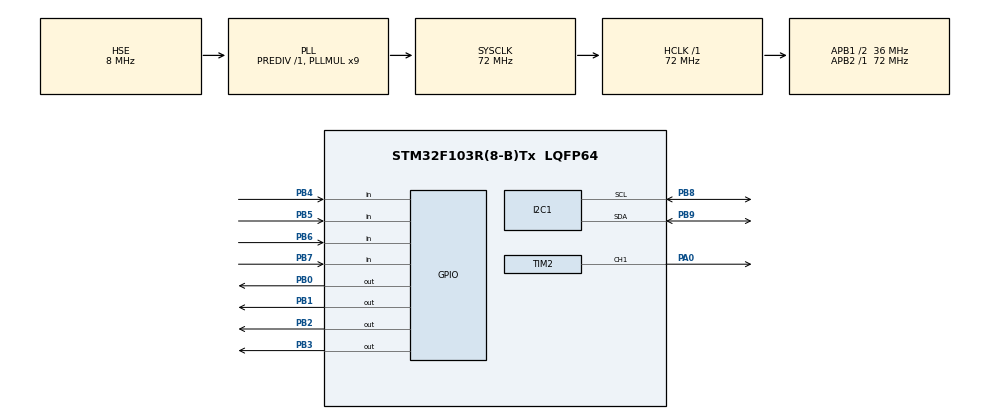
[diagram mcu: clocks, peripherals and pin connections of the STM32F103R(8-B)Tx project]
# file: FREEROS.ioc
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FREERTOS.Mutexes01=angleMutex,Dynamic,NULL,Available
FREERTOS.Tasks01=defaultTask,-2,128,StartDefaultTask,Default,NULL,Dynamic,NULL,NULL;KeypadTask,0,256,StartKeypadTask,Default,NULL,Dynamic,NULL,NULL;ServoTask,1,256,StartServoTask,Default,NULL,Dynamic,NULL,NULL;LCDTask,0,256,StartLCDTask,Default,NULL,Dynamic,NULL,NULL
FREERTOS.configTOTAL_HEAP_SIZE=8192
FREERTOS.configUSE_NEWLIB_REENTRANT=1
Mcu.Family=STM32F1
Mcu.Name=STM32F103R(8-B)Tx
Mcu.Package=LQFP64
NVIC.PriorityGroup=NVIC_PRIORITYGROUP_4
NVIC.TIM1_UP_IRQn=true\:5\:0\:false\:false\:true\:true\:true\:true\:true
NVIC.TIM2_IRQn=true\:5\:0\:false\:false\:true\:true\:true\:true\:true
NVIC.TIM4_IRQn=true\:15\:0\:false\:false\:true\:false\:false\:true\:true
NVIC.TimeBase=TIM4_IRQn
NVIC.TimeBaseIP=TIM4
PA0-WKUP.Signal=S_TIM2_CH1_ETR
PB0.Signal=GPIO_Output
PB1.Signal=GPIO_Output
PB2.Signal=GPIO_Output
PB3.Signal=GPIO_Output
PB4.GPIO_PuPd=GPIO_PULLUP
PB4.Signal=GPIO_Input
PB5.GPIO_PuPd=GPIO_PULLUP
PB5.Signal=GPIO_Input
PB6.GPIO_PuPd=GPIO_PULLUP
PB6.Signal=GPIO_Input
PB7.GPIO_PuPd=GPIO_PULLUP
PB7.Signal=GPIO_Input
PB8.Mode=I2C
PB8.Signal=I2C1_SCL
PB9.Mode=I2C
PB9.Signal=I2C1_SDA
PD0-OSC_IN.Mode=HSE-External-Oscillator
PD0-OSC_IN.Signal=RCC_OSC_IN
PD1-OSC_OUT.Mode=HSE-External-Oscillator
PD1-OSC_OUT.Signal=RCC_OSC_OUT
ProjectManager.HeapSize=0x200
ProjectManager.StackSize=0x400
ProjectManager.TargetToolchain=STM32CubeIDE
RCC.AHBFreq_Value=72000000
RCC.APB1CLKDivider=RCC_HCLK_DIV2
RCC.APB1Freq_Value=36000000
RCC.APB1TimFreq_Value=72000000
RCC.APB2Freq_Value=72000000
RCC.APB2TimFreq_Value=72000000
RCC.HCLKFreq_Value=72000000
RCC.PLLMUL=RCC_PLL_MUL9
RCC.PLLSourceVirtual=RCC_PLLSOURCE_HSE
RCC.SYSCLKFreq_VALUE=72000000
RCC.SYSCLKSource=RCC_SYSCLKSOURCE_PLLCLK
RCC.USBFreq_Value=72000000
SH.S_TIM2_CH1_ETR.0=TIM2_CH1,PWM Generation1 CH1
TIM2.Channel-PWM\ Generation1\ CH1=TIM_CHANNEL_1
TIM2.Period=20 - 1
TIM2.Prescaler=720 - 1
VP_FREERTOS_VS_CMSIS_V1.Mode=CMSIS_V1
VP_SYS_VS_ND.Mode=No_Debug
VP_SYS_VS_tim4.Mode=TIM4
VP_TIM1_VS_ClockSourceINT.Mode=Internal
VP_TIM2_VS_ClockSourceINT.Mode=Internal
board=custom

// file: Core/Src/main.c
/* USER CODE BEGIN Header */
/**
  ******************************************************************************
  * @file           : main.c
  * @brief          : Main program body
  ******************************************************************************
  * @attention
  *
  * Copyright (c) 2026 STMicroelectronics.
  * All rights reserved.
  *
  * This software is licensed under terms that can be found in the LICENSE file
  * in the root directory of this software component.
  * If no LICENSE file comes with this software, it is provided AS-IS.
  *
  ******************************************************************************
  */
/* USER CODE END Header */
#include "main.h"
#include "cmsis_os.h"

/* USER CODE BEGIN Includes */
#include "keypad.h"
#include "lcd_i2c.h"
#include "servo.h"
#include <stdio.h>
#include <string.h>
#include <stdlib.h>
/* USER CODE END Includes */

I2C_HandleTypeDef hi2c1;

TIM_HandleTypeDef htim1;
TIM_HandleTypeDef htim2;

osThreadId defaultTaskHandle;
osThreadId KeypadTaskHandle;
osThreadId ServoTaskHandle;
osThreadId LCDTaskHandle;
osMutexId angleMutexHandle;
/* USER CODE BEGIN PV */
/* Shared variables — all protected by angleMutex */
volatile uint8_t targetAngle = 90;    /* confirmed servo angle (0-180) */
volatile char    inputDisplay[5] = ""; /* digits being typed right now   */
/* USER CODE END PV */

void SystemClock_Config(void);
static void MX_GPIO_Init(void);
static void MX_I2C1_Init(void);
static void MX_TIM1_Init(void);
static void MX_TIM2_Init(void);
void StartDefaultTask(void const * argument);
void StartKeypadTask(void const * argument);
void StartServoTask(void const * argument);
void StartLCDTask(void const * argument);

int main(void)
{

  /* MCU Configuration--------------------------------------------------------*/

  /* Reset of all peripherals, Initializes the Flash interface and the Systick. */
  HAL_Init();

  /* Configure the system clock */
  SystemClock_Config();

  /* Initialize all configured peripherals */
  MX_GPIO_Init();
  MX_I2C1_Init();
  MX_TIM1_Init();
  MX_TIM2_Init();

  /* Create the mutex(es) */
  /* definition and creation of angleMutex */
  osMutexDef(angleMutex);
  angleMutexHandle = osMutexCreate(osMutex(angleMutex));

  /* Create the thread(s) */
  /* definition and creation of defaultTask */
  osThreadDef(defaultTask, StartDefaultTask, osPriorityLow, 0, 128);
  defaultTaskHandle = osThreadCreate(osThread(defaultTask), NULL);

  /* definition and creation of KeypadTask */
  osThreadDef(KeypadTask, StartKeypadTask, osPriorityNormal, 0, 256);
  KeypadTaskHandle = osThreadCreate(osThread(KeypadTask), NULL);

  /* definition and creation of ServoTask */
  osThreadDef(ServoTask, StartServoTask, osPriorityAboveNormal, 0, 256);
  ServoTaskHandle = osThreadCreate(osThread(ServoTask), NULL);

  /* definition and creation of LCDTask */
  osThreadDef(LCDTask, StartLCDTask, osPriorityNormal, 0, 256);
  LCDTaskHandle = osThreadCreate(osThread(LCDTask), NULL);

  /* Start scheduler */
  osKernelStart();

  /* We should never get here as control is now taken by the scheduler */

  /* Infinite loop */
  while (1)
  {

  }
}

void SystemClock_Config(void)
{
  RCC_OscInitTypeDef RCC_OscInitStruct = {0};
  RCC_ClkInitTypeDef RCC_ClkInitStruct = {0};

  /** Initializes the RCC Oscillators according to the specified parameters
  * in the RCC_OscInitTypeDef structure.
  */
  RCC_OscInitStruct.OscillatorType = RCC_OSCILLATORTYPE_HSE;
  RCC_OscInitStruct.HSEState = RCC_HSE_ON;
  RCC_OscInitStruct.HSEPredivValue = RCC_HSE_PREDIV_DIV1;
  RCC_OscInitStruct.HSIState = RCC_HSI_ON;
  RCC_OscInitStruct.PLL.PLLState = RCC_PLL_ON;
  RCC_OscInitStruct.PLL.PLLSource = RCC_PLLSOURCE_HSE;
  RCC_OscInitStruct.PLL.PLLMUL = RCC_PLL_MUL9;
  if (HAL_RCC_OscConfig(&RCC_OscInitStruct) != HAL_OK)
  {
    Error_Handler();
  }

  /** Initializes the CPU, AHB and APB buses clocks
  */
  RCC_ClkInitStruct.ClockType = RCC_CLOCKTYPE_HCLK|RCC_CLOCKTYPE_SYSCLK
                              |RCC_CLOCKTYPE_PCLK1|RCC_CLOCKTYPE_PCLK2;
  RCC_ClkInitStruct.SYSCLKSource = RCC_SYSCLKSOURCE_PLLCLK;
  RCC_ClkInitStruct.AHBCLKDivider = RCC_SYSCLK_DIV1;
  RCC_ClkInitStruct.APB1CLKDivider = RCC_HCLK_DIV2;
  RCC_ClkInitStruct.APB2CLKDivider = RCC_HCLK_DIV1;

  if (HAL_RCC_ClockConfig(&RCC_ClkInitStruct, FLASH_LATENCY_2) != HAL_OK)
  {
    Error_Handler();
  }
}

static void MX_I2C1_Init(void)
{

  hi2c1.Instance = I2C1;
  hi2c1.Init.ClockSpeed = 100000;
  hi2c1.Init.DutyCycle = I2C_DUTYCYCLE_2;
  hi2c1.Init.OwnAddress1 = 0;
  hi2c1.Init.AddressingMode = I2C_ADDRESSINGMODE_7BIT;
  hi2c1.Init.DualAddressMode = I2C_DUALADDRESS_DISABLE;
  hi2c1.Init.OwnAddress2 = 0;
  hi2c1.Init.GeneralCallMode = I2C_GENERALCALL_DISABLE;
  hi2c1.Init.NoStretchMode = I2C_NOSTRETCH_DISABLE;
  if (HAL_I2C_Init(&hi2c1) != HAL_OK)
  {
    Error_Handler();
  }

}

static void MX_TIM1_Init(void)
{

  TIM_ClockConfigTypeDef sClockSourceConfig = {0};
  TIM_MasterConfigTypeDef sMasterConfig = {0};

  htim1.Instance = TIM1;
  htim1.Init.Prescaler = 0;
  htim1.Init.CounterMode = TIM_COUNTERMODE_UP;
  htim1.Init.Period = 65535;
  htim1.Init.ClockDivision = TIM_CLOCKDIVISION_DIV1;
  htim1.Init.RepetitionCounter = 0;
  htim1.Init.AutoReloadPreload = TIM_AUTORELOAD_PRELOAD_DISABLE;
  if (HAL_TIM_Base_Init(&htim1) != HAL_OK)
  {
    Error_Handler();
  }
  sClockSourceConfig.ClockSource = TIM_CLOCKSOURCE_INTERNAL;
  if (HAL_TIM_ConfigClockSource(&htim1, &sClockSourceConfig) != HAL_OK)
  {
    Error_Handler();
  }
  sMasterConfig.MasterOutputTrigger = TIM_TRGO_RESET;
  sMasterConfig.MasterSlaveMode = TIM_MASTERSLAVEMODE_DISABLE;
  if (HAL_TIMEx_MasterConfigSynchronization(&htim1, &sMasterConfig) != HAL_OK)
  {
    Error_Handler();
  }

}

static void MX_TIM2_Init(void)
{

  TIM_ClockConfigTypeDef sClockSourceConfig = {0};
  TIM_MasterConfigTypeDef sMasterConfig = {0};
  TIM_OC_InitTypeDef sConfigOC = {0};

  htim2.Instance = TIM2;
  /* Prescaler=71: 72MHz / 72 = 1MHz (1 tick = 1us)
   * Period=19999: 20000 ticks x 1us = 20ms -> 50Hz (SG90 servo) */
  htim2.Init.Prescaler = 72 - 1;
  htim2.Init.CounterMode = TIM_COUNTERMODE_UP;
  htim2.Init.Period = 20000 - 1;
  htim2.Init.ClockDivision = TIM_CLOCKDIVISION_DIV1;
  htim2.Init.AutoReloadPreload = TIM_AUTORELOAD_PRELOAD_DISABLE;
  if (HAL_TIM_Base_Init(&htim2) != HAL_OK)
  {
    Error_Handler();
  }
  sClockSourceConfig.ClockSource = TIM_CLOCKSOURCE_INTERNAL;
  if (HAL_TIM_ConfigClockSource(&htim2, &sClockSourceConfig) != HAL_OK)
  {
    Error_Handler();
  }
  if (HAL_TIM_PWM_Init(&htim2) != HAL_OK)
  {
    Error_Handler();
  }
  sMasterConfig.MasterOutputTrigger = TIM_TRGO_RESET;
  sMasterConfig.MasterSlaveMode = TIM_MASTERSLAVEMODE_DISABLE;
  if (HAL_TIMEx_MasterConfigSynchronization(&htim2, &sMasterConfig) != HAL_OK)
  {
    Error_Handler();
  }
  sConfigOC.OCMode = TIM_OCMODE_PWM1;
  sConfigOC.Pulse = 0;
  sConfigOC.OCPolarity = TIM_OCPOLARITY_HIGH;
  sConfigOC.OCFastMode = TIM_OCFAST_DISABLE;
  if (HAL_TIM_PWM_ConfigChannel(&htim2, &sConfigOC, TIM_CHANNEL_1) != HAL_OK)
  {
    Error_Handler();
  }
  HAL_TIM_MspPostInit(&htim2);

}

static void MX_GPIO_Init(void)
{
  GPIO_InitTypeDef GPIO_InitStruct = {0};

  /* GPIO Ports Clock Enable */
  __HAL_RCC_GPIOD_CLK_ENABLE();
  __HAL_RCC_GPIOA_CLK_ENABLE();
  __HAL_RCC_GPIOB_CLK_ENABLE();

  /* ── Keypad: Rows PB0-PB3 as push-pull Output (driven LOW to scan) ── */
  HAL_GPIO_WritePin(GPIOB, GPIO_PIN_0|GPIO_PIN_1|GPIO_PIN_2|GPIO_PIN_3, GPIO_PIN_SET);
  GPIO_InitStruct.Pin   = GPIO_PIN_0|GPIO_PIN_1|GPIO_PIN_2|GPIO_PIN_3;
  GPIO_InitStruct.Mode  = GPIO_MODE_OUTPUT_PP;
  GPIO_InitStruct.Pull  = GPIO_NOPULL;
  GPIO_InitStruct.Speed = GPIO_SPEED_FREQ_LOW;
  HAL_GPIO_Init(GPIOB, &GPIO_InitStruct);

  /* ── Keypad: Cols PB4-PB7 as Input with Pull-Up ── */
  GPIO_InitStruct.Pin  = GPIO_PIN_4|GPIO_PIN_5|GPIO_PIN_6|GPIO_PIN_7;
  GPIO_InitStruct.Mode = GPIO_MODE_INPUT;
  GPIO_InitStruct.Pull = GPIO_PULLUP;
  HAL_GPIO_Init(GPIOB, &GPIO_InitStruct);

  /* ── Heartbeat LED: PA5 (Nucleo LD2 on-board User LED) as Output ── */
  HAL_GPIO_WritePin(GPIOA, GPIO_PIN_5, GPIO_PIN_RESET);
  GPIO_InitStruct.Pin   = GPIO_PIN_5;
  GPIO_InitStruct.Mode  = GPIO_MODE_OUTPUT_PP;
  GPIO_InitStruct.Pull  = GPIO_NOPULL;
  GPIO_InitStruct.Speed = GPIO_SPEED_FREQ_LOW;
  HAL_GPIO_Init(GPIOA, &GPIO_InitStruct);

}

void StartDefaultTask(void const * argument)
{
  /* USER CODE BEGIN 5 */
  /* Heartbeat: toggle Nucleo LD2 (PA5) every 3 s.
   * Satisfies lab req: "Toggle an LED every 3 seconds (as a testing task)."
   * PA5 is already configured as output by MX_GPIO_Init(). */
  for(;;)
  {
    HAL_GPIO_TogglePin(GPIOA, GPIO_PIN_5);
    osDelay(3000);
  }
  /* USER CODE END 5 */
}

void StartKeypadTask(void const * argument)
{
  /* USER CODE BEGIN StartKeypadTask */
  /* Task 1 - Keypad Input Task
   * - Continuously scans for user input
   * - Stores the entered angle (0-180) for servo control
   * - Handles debouncing (done inside Keypad_GetKey) and LCD updates
   * - '*' deletes last digit, '#' confirms entry
   */
  Keypad_Init();

  char inputBuf[4] = {0};  /* up to "180" + null */
  uint8_t inputIdx = 0;

  for(;;)
  {
    char key = Keypad_GetKey();

    if (key == NO_KEY)
    {
      osDelay(10);
      continue;
    }

    if (key == '*')
    {
      /* Backspace: remove last digit */
      if (inputIdx > 0)
        inputBuf[--inputIdx] = '\0';
    }
    else if (key == '#')
    {
      /* Confirm: parse angle, clamp to 0-180, update servo target */
      if (inputIdx > 0)
      {
        int angle = atoi(inputBuf);
        if (angle < 0)   angle = 0;
        if (angle > 180) angle = 180;

        osMutexWait(angleMutexHandle, osWaitForever);
        targetAngle = (uint8_t)angle;
        osMutexRelease(angleMutexHandle);
      }
      /* Clear input buffer after confirmation */
      memset(inputBuf, 0, sizeof(inputBuf));
      inputIdx = 0;
    }
    else if (key >= '0' && key <= '9' && inputIdx < 3)
    {
      /* Accumulate digit (max 3 digits for "180") */
      inputBuf[inputIdx++] = key;
      inputBuf[inputIdx]   = '\0';
    }
    /* Ignore A/B/C/D keys */

    /* ── Update shared display buffer so LCD shows live typing ── */
    osMutexWait(angleMutexHandle, osWaitForever);
    strncpy((char *)inputDisplay, inputBuf, sizeof(inputDisplay) - 1);
    inputDisplay[sizeof(inputDisplay) - 1] = '\0';
    osMutexRelease(angleMutexHandle);

    osDelay(10);
  }
  /* USER CODE END StartKeypadTask */
}

void StartServoTask(void const * argument)
{
  /* USER CODE BEGIN StartServoTask */
  /* Task 2 - Servo Control Task
   * - Reads the shared target angle
   * - Adjusts the SG90 servo motor position via hardware PWM (TIM2 CH1)
   * - Uses timer interrupts to generate PWM signals (50 Hz, 20ms period)
   */
  Servo_Init(&htim2);

  for(;;)
  {
    osMutexWait(angleMutexHandle, osWaitForever);
    uint8_t angle = targetAngle;
    osMutexRelease(angleMutexHandle);

    Servo_SetAngle(angle);

    osDelay(20); /* update at 50 Hz to match servo PWM period */
  }
  /* USER CODE END StartServoTask */
}

void StartLCDTask(void const * argument)
{
  /* USER CODE BEGIN StartLCDTask */
  /* Task 3 - LCD Update Task
   * Line 0 (top)   : "Enter: XXX_    "  <- live typing, '_' = cursor
   * Line 1 (bottom): "Set:   XXX deg "  <- last confirmed angle
   */
  LCD_Init(&hi2c1);
  LCD_Clear();

  uint8_t cursorVisible = 1; /* blink state */
  uint8_t blinkCount   = 0;

  for(;;)
  {
    /* Read both shared values under one mutex lock */
    osMutexWait(angleMutexHandle, osWaitForever);
    uint8_t angle = targetAngle;
    char    typing[5];
    strncpy(typing, (const char *)inputDisplay, sizeof(typing));
    typing[sizeof(typing) - 1] = '\0';
    osMutexRelease(angleMutexHandle);

    /* ── Line 0: live typing with blinking underscore cursor ── */
    char row0[17];
    uint8_t len = (uint8_t)strlen(typing);
    /* Build: "Enter: 9_       " */
    if (cursorVisible)
      snprintf(row0, sizeof(row0), "Enter: %-3s_     ", typing);
    else
      snprintf(row0, sizeof(row0), "Enter: %-3s      ", typing);

    LCD_SetCursor(0, 0);
    LCD_WriteString(row0);

    /* ── Line 1: confirmed servo angle ── */
    char row1[17];
    snprintf(row1, sizeof(row1), "Set:  %3d deg   ", angle);
    LCD_SetCursor(0, 1);
    LCD_WriteString(row1);

    /* Blink cursor every 3 refreshes (3 x 150ms = ~450ms) */
    blinkCount++;
    if (blinkCount >= 3)
    {
      cursorVisible ^= 1;
      blinkCount = 0;
    }
    (void)len; /* suppress unused warning */

    osDelay(150); /* refresh at ~6.7 Hz */
  }
  /* USER CODE END StartLCDTask */
}

void HAL_TIM_PeriodElapsedCallback(TIM_HandleTypeDef *htim)
{
  if (htim->Instance == TIM4)
  {
    HAL_IncTick();
  }
}

void Error_Handler(void)
{
  __disable_irq();
  while (1)
  {
  }
}
